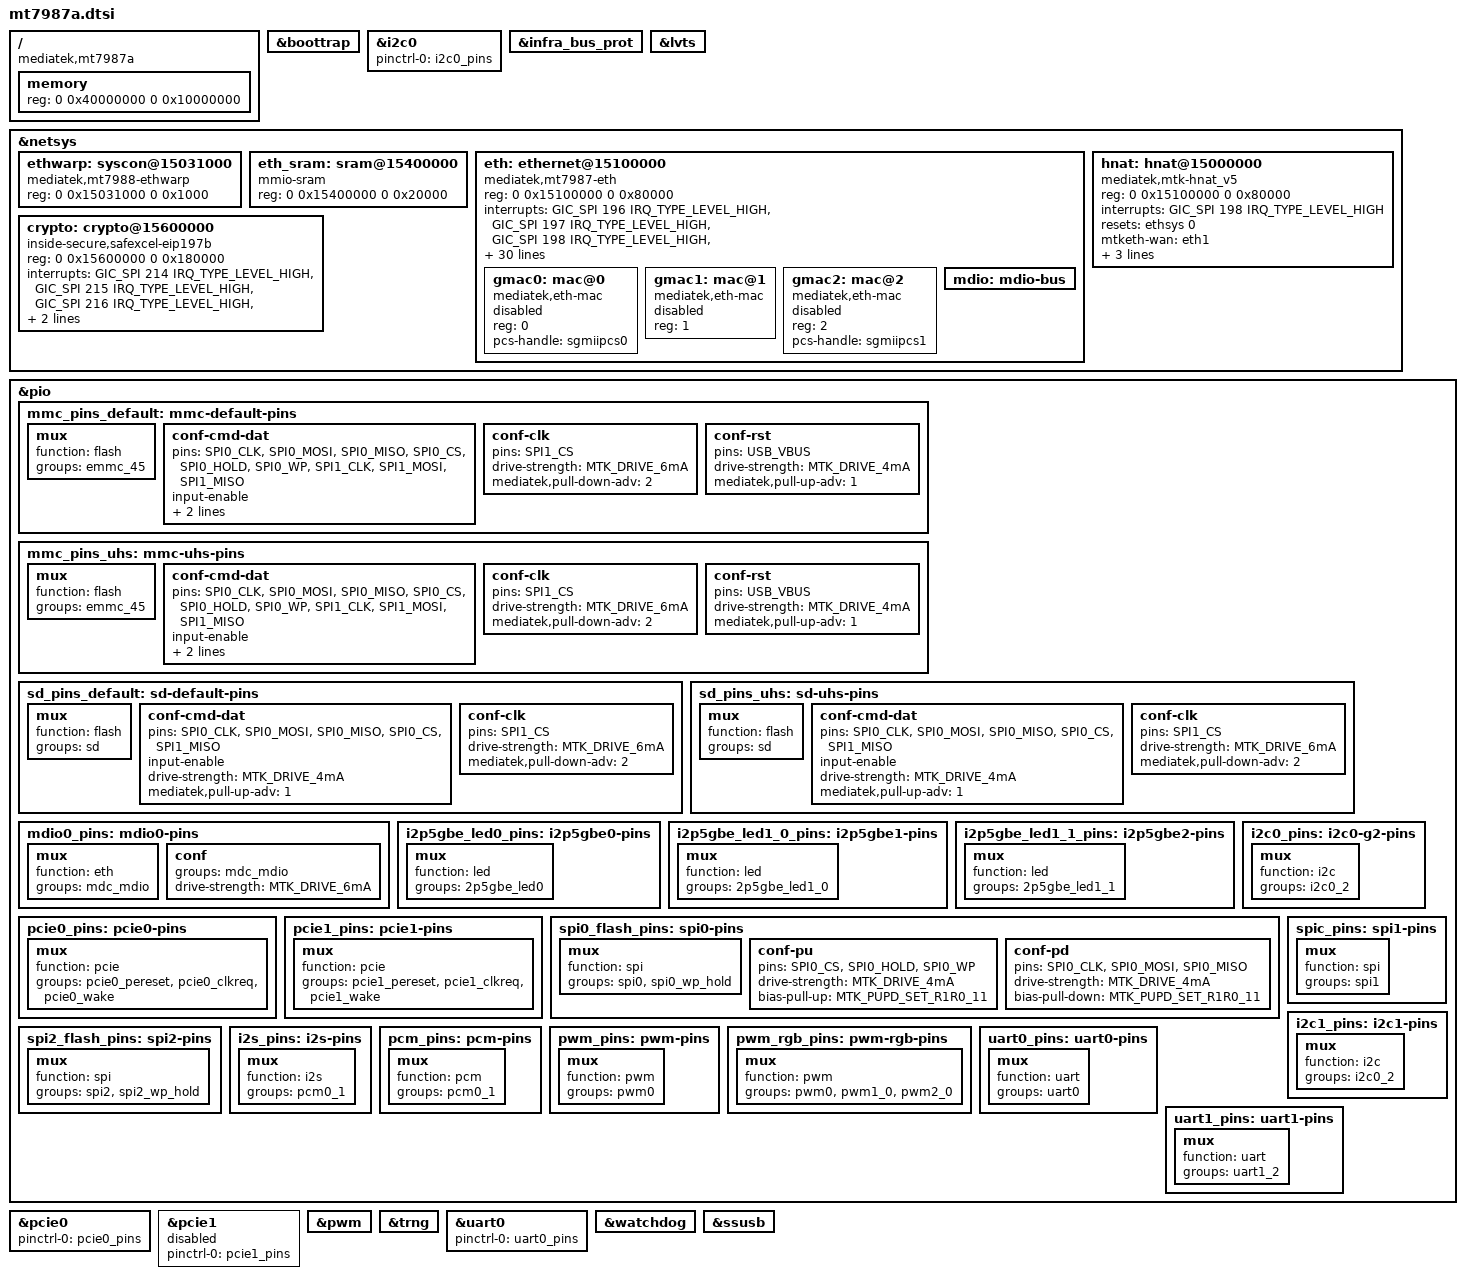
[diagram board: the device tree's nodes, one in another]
// SPDX-License-Identifier: (GPL-2.0 OR MIT)
/*
 * Copyright (C) 2023 MediaTek Inc.
 * Author: Sam.Shih <sam.shih@mediatek.com>
 */

/dts-v1/;

#include <dt-bindings/leds/common.h>
#include <dt-bindings/interrupt-controller/irq.h>
#include <dt-bindings/interrupt-controller/arm-gic.h>
#include <dt-bindings/phy/phy.h>
#include <dt-bindings/reset/ti-syscon.h>
#include <dt-bindings/clock/mediatek,mt7987-clk.h>
#include <dt-bindings/pinctrl/mt65xx.h>

#include "mt7987.dtsi"

/ {
	compatible = "mediatek,mt7987a", "mediatek,mt7987";
	memory {
		reg = <0 0x40000000 0 0x10000000>;
	};
};

&boottrap {
	status = "okay";
};

&i2c0 {
	pinctrl-names = "default";
	pinctrl-0 = <&i2c0_pins>;
	status = "okay";
};

&infra_bus_prot {
	status = "okay";
};

&lvts {
	status = "okay";
};

&netsys {
	ethwarp: syscon@15031000 {
		compatible = "mediatek,mt7988-ethwarp", "syscon";
		reg = <0 0x15031000 0 0x1000>;
		#clock-cells = <1>;
	};

	eth_sram: sram@15400000 {
		compatible = "mmio-sram";
		reg = <0 0x15400000 0 0x20000>;
		#address-cells = <1>;
		#size-cells = <1>;
		ranges = <0 0x15400000 0 0x20000>;
	};

	eth: ethernet@15100000 {
		compatible = "mediatek,mt7987-eth";
		reg = <0 0x15100000 0 0x80000>;
		interrupts = <GIC_SPI 196 IRQ_TYPE_LEVEL_HIGH>,
			     <GIC_SPI 197 IRQ_TYPE_LEVEL_HIGH>,
			     <GIC_SPI 198 IRQ_TYPE_LEVEL_HIGH>,
			     <GIC_SPI 199 IRQ_TYPE_LEVEL_HIGH>,
			     <GIC_SPI 189 IRQ_TYPE_LEVEL_HIGH>,
			     <GIC_SPI 190 IRQ_TYPE_LEVEL_HIGH>,
			     <GIC_SPI 191 IRQ_TYPE_LEVEL_HIGH>,
			     <GIC_SPI 192 IRQ_TYPE_LEVEL_HIGH>;
		interrupt-names = "fe0","fe1","fe2","fe3",
				  "pdma0","pdma1","pdma2","pdma3";
		clocks = <&ethsys CLK_ETHDMA_FE_EN>,
			 <&ethsys CLK_ETHDMA_GP2_EN>,
			 <&ethsys CLK_ETHDMA_GP1_EN>,
			 <&ethsys CLK_ETHDMA_GP3_EN>,
			 <&topckgen CLK_TOP_ETH_GMII_SEL>,
			 <&topckgen CLK_TOP_ETH_REFCK_50M_SEL>,
			 <&topckgen CLK_TOP_ETH_SYS_200M_SEL>,
			 <&topckgen CLK_TOP_ETH_SYS_SEL>,
			 <&topckgen CLK_TOP_ETH_XGMII_SEL>,
			 <&topckgen CLK_TOP_ETH_MII_SEL>,
			 <&topckgen CLK_TOP_NETSYS_SEL>,
			 <&topckgen CLK_TOP_NETSYS_500M_SEL>,
			 <&topckgen CLK_TOP_NETSYS_2X_SEL>;
		clock-names = "fe", "gp2", "gp1", "gp3",
			      "top_eth_gmii_sel", "top_eth_refck_50m_sel",
			      "top_eth_sys_200m_sel", "top_eth_sys_sel",
			      "top_eth_xgmii_sel", "top_eth_mii_sel",
			      "top_netsys_sel", "top_netsys_500m_sel",
			      "top_netsys_pao_2x_sel";
		assigned-clocks = <&topckgen CLK_TOP_NETSYS_2X_SEL>,
				  <&topckgen CLK_TOP_SGM_0_SEL>,
				  <&topckgen CLK_TOP_SGM_1_SEL>;
		assigned-clock-parents = <&apmixedsys CLK_APMIXED_NET2PLL>,
					 <&apmixedsys CLK_APMIXED_SGMPLL>,
					 <&apmixedsys CLK_APMIXED_SGMPLL>;
		mediatek,ethsys = <&ethsys>;
		mediatek,infracfg = <&topmisc>;
		pinctrl-names = "default";
		pinctrl-0 = <&mdio0_pins>;
		#reset-cells = <1>;
		#address-cells = <1>;
		#size-cells = <0>;
		sram = <&eth_sram>;
		status = "disabled";
		gmac0: mac@0 {
			compatible = "mediatek,eth-mac";
			reg = <0>;
			pcs-handle = <&sgmiipcs0>;
			status = "disabled";
		};
		gmac1: mac@1 {
			compatible = "mediatek,eth-mac";
			reg = <1>;
			status = "disabled";
		};
		gmac2: mac@2 {
			compatible = "mediatek,eth-mac";
			reg = <2>;
			pcs-handle = <&sgmiipcs1>;
			status = "disabled";
		};
		mdio: mdio-bus {
			#address-cells = <1>;
			#size-cells = <0>;
		};
	};

	hnat: hnat@15000000 {
		compatible = "mediatek,mtk-hnat_v5";
		reg = <0 0x15100000 0 0x80000>;
		interrupts = <GIC_SPI 198 IRQ_TYPE_LEVEL_HIGH>;
		resets = <&ethsys 0>;
		reset-names = "mtketh";
		status = "disabled";
	};

	crypto: crypto@15600000 {
		compatible = "inside-secure,safexcel-eip197b",
			     "security-ip-197-srv";
		reg = <0 0x15600000 0 0x180000>;
		interrupts = <GIC_SPI 214 IRQ_TYPE_LEVEL_HIGH>,
			     <GIC_SPI 215 IRQ_TYPE_LEVEL_HIGH>,
			     <GIC_SPI 216 IRQ_TYPE_LEVEL_HIGH>,
			     <GIC_SPI 217 IRQ_TYPE_LEVEL_HIGH>;
		interrupt-names = "ring0", "ring1", "ring2", "ring3";
		eth = <&eth>;
		status = "disabled";
	};
};

&crypto {
	status = "okay";
};

&eth {
	status = "okay";
};

&hnat {
	mtketh-wan = "eth1";
	mtketh-lan = "lan";
	mtketh-max-gmac = <2>;
	mtketh-ppe-num = <1>;
	status = "okay";
};

&pio {
	mmc_pins_default: mmc-default-pins {
		mux {
			function = "flash";
			groups = "emmc_45";
		};
		conf-cmd-dat {
			pins = "SPI0_CLK", "SPI0_MOSI", "SPI0_MISO",
			       "SPI0_CS", "SPI0_HOLD", "SPI0_WP",
			       "SPI1_CLK", "SPI1_MOSI", "SPI1_MISO";
			input-enable;
			drive-strength = <MTK_DRIVE_4mA>;
			mediatek,pull-up-adv = <1>;	/* pull-up 10K */
		};
		conf-clk {
			pins = "SPI1_CS";
			drive-strength = <MTK_DRIVE_6mA>;
			mediatek,pull-down-adv = <2>;	/* pull-down 50K */
		};
		conf-rst {
			pins = "USB_VBUS";
			drive-strength = <MTK_DRIVE_4mA>;
			mediatek,pull-up-adv = <1>;	/* pull-up 10K */
		};
	};
	mmc_pins_uhs: mmc-uhs-pins {
		mux {
			function = "flash";
			groups = "emmc_45";
		};
		conf-cmd-dat {
			pins = "SPI0_CLK", "SPI0_MOSI", "SPI0_MISO",
			       "SPI0_CS", "SPI0_HOLD", "SPI0_WP",
			       "SPI1_CLK", "SPI1_MOSI", "SPI1_MISO";
			input-enable;
			drive-strength = <MTK_DRIVE_4mA>;
			mediatek,pull-up-adv = <1>;	/* pull-up 10K */
		};
		conf-clk {
			pins = "SPI1_CS";
			drive-strength = <MTK_DRIVE_6mA>;
			mediatek,pull-down-adv = <2>;	/* pull-down 50K */
		};
		conf-rst {
			pins = "USB_VBUS";
			drive-strength = <MTK_DRIVE_4mA>;
			mediatek,pull-up-adv = <1>;	/* pull-up 10K */
		};
	};
	sd_pins_default: sd-default-pins {
		mux {
			function = "flash";
			groups = "sd";
		};
		conf-cmd-dat {
			pins = "SPI0_CLK", "SPI0_MOSI", "SPI0_MISO",
			       "SPI0_CS", "SPI1_MISO";
			input-enable;
			drive-strength = <MTK_DRIVE_4mA>;
			mediatek,pull-up-adv = <1>;	/* pull-up 10K */
		};
		conf-clk {
			pins = "SPI1_CS";
			drive-strength = <MTK_DRIVE_6mA>;
			mediatek,pull-down-adv = <2>;	/* pull-down 50K */
		};
	};
	sd_pins_uhs: sd-uhs-pins {
		mux {
			function = "flash";
			groups = "sd";
		};
		conf-cmd-dat {
			pins = "SPI0_CLK", "SPI0_MOSI", "SPI0_MISO",
			       "SPI0_CS", "SPI1_MISO";
			input-enable;
			drive-strength = <MTK_DRIVE_4mA>;
			mediatek,pull-up-adv = <1>;	/* pull-up 10K */
		};
		conf-clk {
			pins = "SPI1_CS";
			drive-strength = <MTK_DRIVE_6mA>;
			mediatek,pull-down-adv = <2>;	/* pull-down 50K */
		};
	};
	mdio0_pins: mdio0-pins {
		mux {
			function = "eth";
			groups = "mdc_mdio";
		};
		conf {
			groups = "mdc_mdio";
			drive-strength = <MTK_DRIVE_6mA>;
		};
	};
	i2p5gbe_led0_pins: i2p5gbe0-pins {
		mux {
			function = "led";
			groups = "2p5gbe_led0";
		};
	};
	i2p5gbe_led1_0_pins: i2p5gbe1-pins {
		mux {
			function = "led";
			groups = "2p5gbe_led1_0";
		};
	};
	i2p5gbe_led1_1_pins: i2p5gbe2-pins {
		mux {
			function = "led";
			groups = "2p5gbe_led1_1";
		};
	};
	i2c0_pins: i2c0-g2-pins {
		mux {
			function = "i2c";
			groups = "i2c0_2";
		};
	};
	pcie0_pins: pcie0-pins {
		mux {
			function = "pcie";
			groups = "pcie0_pereset", "pcie0_clkreq",
				 "pcie0_wake";
		};
	};
	pcie1_pins: pcie1-pins {
		mux {
			function = "pcie";
			groups = "pcie1_pereset", "pcie1_clkreq",
				 "pcie1_wake";
		};
	};
	spi0_flash_pins: spi0-pins {
		mux {
			function = "spi";
			groups = "spi0", "spi0_wp_hold";
		};
		conf-pu {
			pins = "SPI0_CS", "SPI0_HOLD", "SPI0_WP";
			drive-strength = <MTK_DRIVE_4mA>;
			bias-pull-up = <MTK_PUPD_SET_R1R0_11>;
		};
		conf-pd {
			pins = "SPI0_CLK", "SPI0_MOSI", "SPI0_MISO";
			drive-strength = <MTK_DRIVE_4mA>;
			bias-pull-down = <MTK_PUPD_SET_R1R0_11>;
		};
	};
	spic_pins: spi1-pins {
		mux {
			function = "spi";
			groups = "spi1";
		};
	};
	spi2_flash_pins: spi2-pins {
		mux {
			function = "spi";
			groups = "spi2", "spi2_wp_hold";
		};
	};
	i2c1_pins: i2c1-pins {
		mux {
			function = "i2c";
			groups = "i2c0_2";
		};
	};
	i2s_pins: i2s-pins {
		mux {
			function = "i2s";
			groups = "pcm0_1";
		};
	};
	pcm_pins: pcm-pins {
		mux {
			function = "pcm";
			groups = "pcm0_1";
		};
	};
	pwm_pins: pwm-pins {
		mux {
			/*
			 * - pwm0   : PWM0@PIN13
			 * - pwm1_0 : PWM1@PIN7  (share with JTAG)
			 *   pwm1_1 : PWM1@PIN43 (share with i2c0)
			 * - pwm2_0 : PWM2@PIN12 (share with PCM)
			 *   pwm2_1 : PWM2@PIN44 (share with i2c0)
			 */
			function = "pwm";
			groups = "pwm0";
		};
	};
	pwm_rgb_pins: pwm-rgb-pins {
		mux {
			/*
			* - pwm0 1  : PWM0@PIN13
			* - pwm1_0 :; PWM@PIN7  (share with JTAG)
			*   pwm1_1 : PWM1@PIN43 (share with i2c0)
			* - pwm2_0 : PWM2@PIN12 (share with PCM)
			*   pwm2_1 : PWM2@PIN44 (share with i2c0)
			*/
			function = "pwm";
			groups = "pwm0", "pwm1_0", "pwm2_0";
		};
	};
	uart0_pins: uart0-pins {
		mux {
			function = "uart";
			groups = "uart0";
		};
	};
	uart1_pins: uart1-pins {
		mux {
			function = "uart";
			groups = "uart1_2";
		};
	};
};

&pcie0 {
	pinctrl-names = "default";
	pinctrl-0 = <&pcie0_pins>;
	status = "okay";
};

&pcie1 {
	pinctrl-names = "default";
	pinctrl-0 = <&pcie1_pins>;
	status = "disabled";
};

&pwm {
	status = "okay";
};

&trng {
	status = "okay";
};

&uart0 {
	pinctrl-names = "default";
	pinctrl-0 = <&uart0_pins>;
	status = "okay";
};

&watchdog {
	status = "okay";
};

&ssusb {
	status = "okay";
};
